VERSION "amr_vehicle K2 v1 (Ausbaupaket K2, Phasenplan v2.1)"

NS_ :

BS_:

BU_: PI_VCU DRIVE_ECU SENSOR_ECU RADAR_ECU

BO_ 272 SENSOR_RANGE: 4 SENSOR_ECU
 SG_ range_front : 0|32@1+ (1,0) [0|4] "m"  PI_VCU

BO_ 288 SENSOR_CLIFF: 1 SENSOR_ECU
 SG_ cliff_detected : 0|8@1+ (1,0) [0|1] ""  PI_VCU,DRIVE_ECU

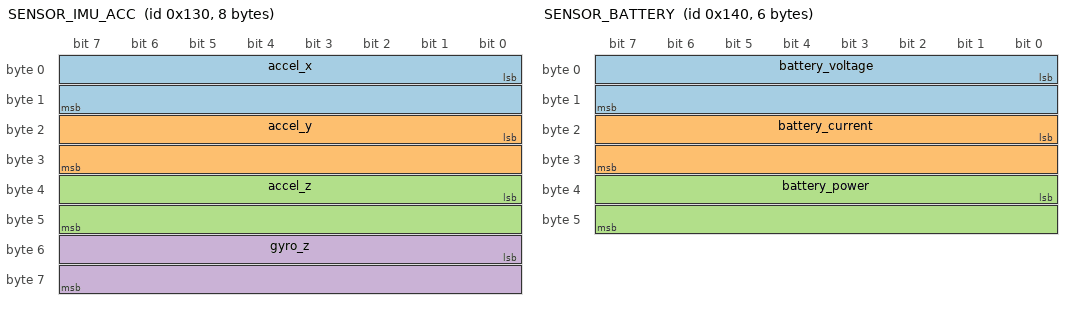
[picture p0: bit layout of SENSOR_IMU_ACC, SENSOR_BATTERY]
BO_ 304 SENSOR_IMU_ACC: 8 SENSOR_ECU
 SG_ accel_x : 0|16@1- (0.001,0) [-32.768|32.767] "m/s^2"  PI_VCU
 SG_ accel_y : 16|16@1- (0.001,0) [-32.768|32.767] "m/s^2"  PI_VCU
 SG_ accel_z : 32|16@1- (0.001,0) [-32.768|32.767] "m/s^2"  PI_VCU
 SG_ gyro_z : 48|16@1- (0.01,0) [-327.68|327.67] "rad/s"  PI_VCU

BO_ 305 SENSOR_IMU_HEADING: 4 SENSOR_ECU
 SG_ heading : 0|32@1+ (1,0) [-3.2|3.2] "rad"  PI_VCU

BO_ 320 SENSOR_BATTERY: 6 SENSOR_ECU
 SG_ battery_voltage : 0|16@1+ (0.001,0) [0|65.535] "V"  PI_VCU
 SG_ battery_current : 16|16@1- (0.001,0) [-32.768|32.767] "A"  PI_VCU
 SG_ battery_power : 32|16@1+ (0.001,0) [0|65.535] "W"  PI_VCU

BO_ 321 SENSOR_BATTERY_SHUTDOWN: 1 SENSOR_ECU
 SG_ battery_shutdown : 0|8@1+ (1,0) [0|1] ""  PI_VCU,DRIVE_ECU

BO_ 336 VCU_SERVO_COMMAND_LEGACY: 4 PI_VCU
 SG_ servo_pan_legacy : 0|16@1- (0.1,0) [-180|180] "deg"  SENSOR_ECU
 SG_ servo_tilt_legacy : 16|16@1- (0.1,0) [-180|180] "deg"  SENSOR_ECU

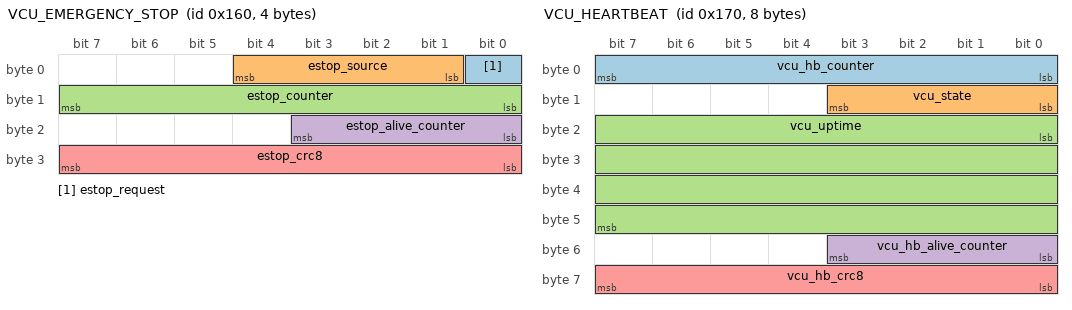
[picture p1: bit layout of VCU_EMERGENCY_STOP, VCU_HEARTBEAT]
BO_ 352 VCU_EMERGENCY_STOP: 4 PI_VCU
 SG_ estop_request : 0|1@1+ (1,0) [0|1] ""  DRIVE_ECU,SENSOR_ECU
 SG_ estop_source : 1|4@1+ (1,0) [0|15] ""  DRIVE_ECU,SENSOR_ECU
 SG_ estop_counter : 8|8@1+ (1,0) [0|255] ""  DRIVE_ECU,SENSOR_ECU
 SG_ estop_alive_counter : 16|4@1+ (1,0) [0|15] ""  DRIVE_ECU,SENSOR_ECU
 SG_ estop_crc8 : 24|8@1+ (1,0) [0|255] ""  DRIVE_ECU,SENSOR_ECU

BO_ 368 VCU_HEARTBEAT: 8 PI_VCU
 SG_ vcu_hb_counter : 0|8@1+ (1,0) [0|255] ""  DRIVE_ECU,SENSOR_ECU
 SG_ vcu_state : 8|4@1+ (1,0) [0|15] ""  DRIVE_ECU,SENSOR_ECU
 SG_ vcu_uptime : 16|32@1+ (1,0) [0|4294967295] "s"  DRIVE_ECU,SENSOR_ECU
 SG_ vcu_hb_alive_counter : 48|4@1+ (1,0) [0|15] ""  DRIVE_ECU,SENSOR_ECU
 SG_ vcu_hb_crc8 : 56|8@1+ (1,0) [0|255] ""  DRIVE_ECU,SENSOR_ECU

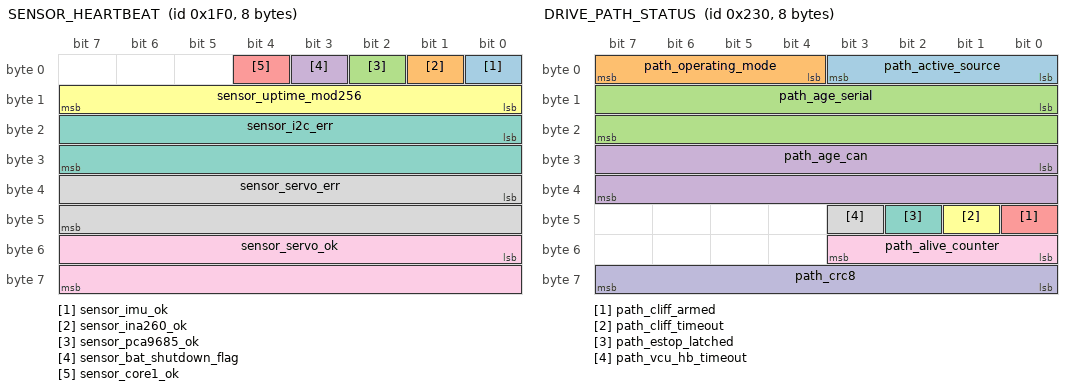
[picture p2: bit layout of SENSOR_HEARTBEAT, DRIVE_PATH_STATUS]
BO_ 496 SENSOR_HEARTBEAT: 8 SENSOR_ECU
 SG_ sensor_imu_ok : 0|1@1+ (1,0) [0|1] ""  PI_VCU
 SG_ sensor_ina260_ok : 1|1@1+ (1,0) [0|1] ""  PI_VCU
 SG_ sensor_pca9685_ok : 2|1@1+ (1,0) [0|1] ""  PI_VCU
 SG_ sensor_bat_shutdown_flag : 3|1@1+ (1,0) [0|1] ""  PI_VCU
 SG_ sensor_core1_ok : 4|1@1+ (1,0) [0|1] ""  PI_VCU
 SG_ sensor_uptime_mod256 : 8|8@1+ (1,0) [0|255] "s"  PI_VCU
 SG_ sensor_i2c_err : 16|16@1+ (1,0) [0|65535] ""  PI_VCU
 SG_ sensor_servo_err : 32|16@1+ (1,0) [0|65535] ""  PI_VCU
 SG_ sensor_servo_ok : 48|16@1+ (1,0) [0|65535] ""  PI_VCU

BO_ 512 DRIVE_ODOM_XY: 8 DRIVE_ECU
 SG_ odom_x : 0|32@1+ (1,0) [-100|100] "m"  PI_VCU
 SG_ odom_y : 32|32@1+ (1,0) [-100|100] "m"  PI_VCU

BO_ 513 DRIVE_ODOM_HEADING_SPEED: 8 DRIVE_ECU
 SG_ odom_theta : 0|32@1+ (1,0) [-3.2|3.2] "rad"  PI_VCU
 SG_ odom_v_linear : 32|32@1+ (1,0) [-1|1] "m/s"  PI_VCU

BO_ 528 DRIVE_WHEEL_SPEED: 8 DRIVE_ECU
 SG_ wheel_speed_left : 0|32@1+ (1,0) [-50|50] "rad/s"  PI_VCU
 SG_ wheel_speed_right : 32|32@1+ (1,0) [-50|50] "rad/s"  PI_VCU

BO_ 544 DRIVE_MOTOR_PWM: 4 DRIVE_ECU
 SG_ motor_pwm_left : 0|16@1- (1,0) [-255|255] ""  PI_VCU
 SG_ motor_pwm_right : 16|16@1- (1,0) [-255|255] ""  PI_VCU

BO_ 560 DRIVE_PATH_STATUS: 8 DRIVE_ECU
 SG_ path_active_source : 0|4@1+ (1,0) [0|15] ""  PI_VCU
 SG_ path_operating_mode : 4|4@1+ (1,0) [0|15] ""  PI_VCU
 SG_ path_age_serial : 8|16@1+ (1,0) [0|65535] "ms"  PI_VCU
 SG_ path_age_can : 24|16@1+ (1,0) [0|65535] "ms"  PI_VCU
 SG_ path_cliff_armed : 40|1@1+ (1,0) [0|1] ""  PI_VCU
 SG_ path_cliff_timeout : 41|1@1+ (1,0) [0|1] ""  PI_VCU
 SG_ path_estop_latched : 42|1@1+ (1,0) [0|1] ""  PI_VCU
 SG_ path_vcu_hb_timeout : 43|1@1+ (1,0) [0|1] ""  PI_VCU
 SG_ path_alive_counter : 48|4@1+ (1,0) [0|15] ""  PI_VCU
 SG_ path_crc8 : 56|8@1+ (1,0) [0|255] ""  PI_VCU

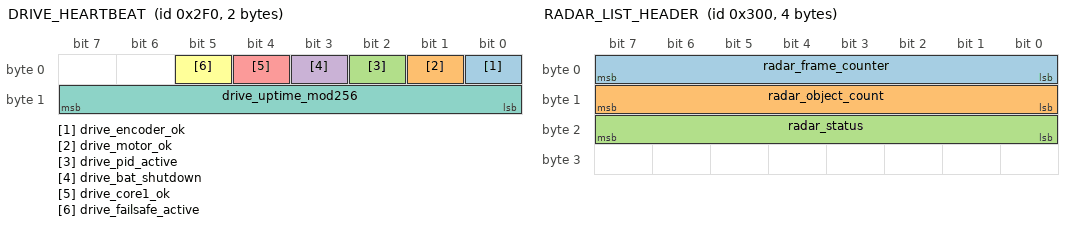
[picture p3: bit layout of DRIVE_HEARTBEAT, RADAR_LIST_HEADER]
BO_ 752 DRIVE_HEARTBEAT: 2 DRIVE_ECU
 SG_ drive_encoder_ok : 0|1@1+ (1,0) [0|1] ""  PI_VCU
 SG_ drive_motor_ok : 1|1@1+ (1,0) [0|1] ""  PI_VCU
 SG_ drive_pid_active : 2|1@1+ (1,0) [0|1] ""  PI_VCU
 SG_ drive_bat_shutdown : 3|1@1+ (1,0) [0|1] ""  PI_VCU
 SG_ drive_core1_ok : 4|1@1+ (1,0) [0|1] ""  PI_VCU
 SG_ drive_failsafe_active : 5|1@1+ (1,0) [0|1] ""  PI_VCU
 SG_ drive_uptime_mod256 : 8|8@1+ (1,0) [0|255] "s"  PI_VCU

BO_ 768 RADAR_LIST_HEADER: 4 RADAR_ECU
 SG_ radar_frame_counter : 0|8@1+ (1,0) [0|255] ""  PI_VCU
 SG_ radar_object_count : 8|8@1+ (1,0) [0|8] ""  PI_VCU
 SG_ radar_status : 16|8@1+ (1,0) [0|255] ""  PI_VCU

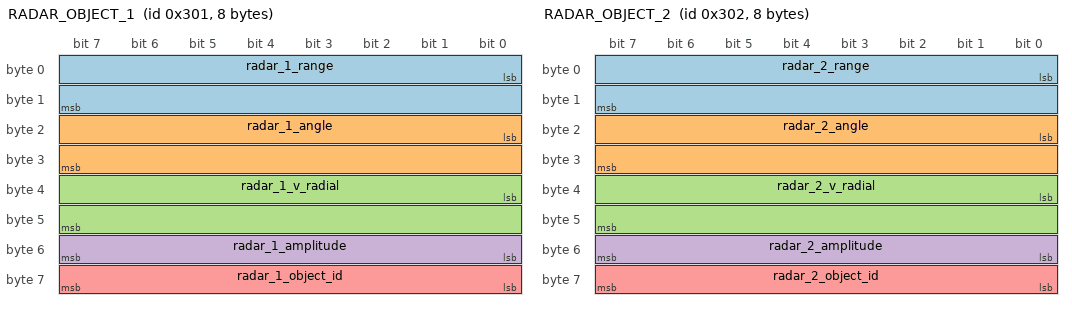
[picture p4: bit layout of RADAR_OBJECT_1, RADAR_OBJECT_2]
BO_ 769 RADAR_OBJECT_1: 8 RADAR_ECU
 SG_ radar_1_range : 0|16@1+ (0.001,0) [0|65.535] "m"  PI_VCU
 SG_ radar_1_angle : 16|16@1- (0.01,0) [-327.68|327.67] "deg"  PI_VCU
 SG_ radar_1_v_radial : 32|16@1- (0.01,0) [-327.68|327.67] "m/s"  PI_VCU
 SG_ radar_1_amplitude : 48|8@1+ (1,0) [0|255] ""  PI_VCU
 SG_ radar_1_object_id : 56|8@1+ (1,0) [0|255] ""  PI_VCU

BO_ 770 RADAR_OBJECT_2: 8 RADAR_ECU
 SG_ radar_2_range : 0|16@1+ (0.001,0) [0|65.535] "m"  PI_VCU
 SG_ radar_2_angle : 16|16@1- (0.01,0) [-327.68|327.67] "deg"  PI_VCU
 SG_ radar_2_v_radial : 32|16@1- (0.01,0) [-327.68|327.67] "m/s"  PI_VCU
 SG_ radar_2_amplitude : 48|8@1+ (1,0) [0|255] ""  PI_VCU
 SG_ radar_2_object_id : 56|8@1+ (1,0) [0|255] ""  PI_VCU

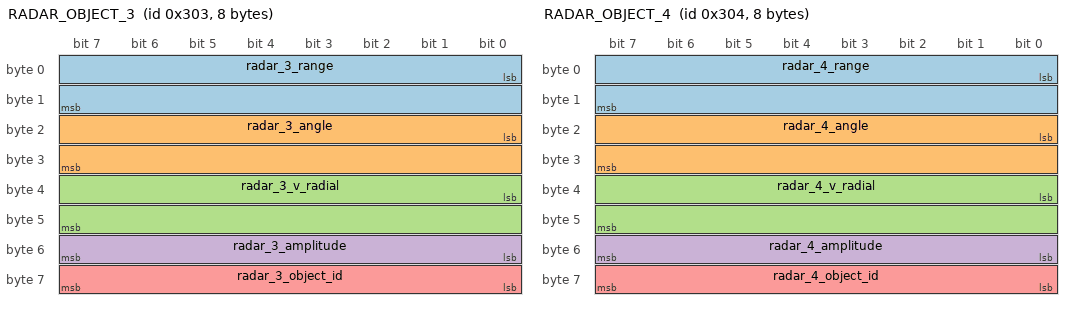
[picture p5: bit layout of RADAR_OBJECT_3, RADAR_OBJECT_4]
BO_ 771 RADAR_OBJECT_3: 8 RADAR_ECU
 SG_ radar_3_range : 0|16@1+ (0.001,0) [0|65.535] "m"  PI_VCU
 SG_ radar_3_angle : 16|16@1- (0.01,0) [-327.68|327.67] "deg"  PI_VCU
 SG_ radar_3_v_radial : 32|16@1- (0.01,0) [-327.68|327.67] "m/s"  PI_VCU
 SG_ radar_3_amplitude : 48|8@1+ (1,0) [0|255] ""  PI_VCU
 SG_ radar_3_object_id : 56|8@1+ (1,0) [0|255] ""  PI_VCU

BO_ 772 RADAR_OBJECT_4: 8 RADAR_ECU
 SG_ radar_4_range : 0|16@1+ (0.001,0) [0|65.535] "m"  PI_VCU
 SG_ radar_4_angle : 16|16@1- (0.01,0) [-327.68|327.67] "deg"  PI_VCU
 SG_ radar_4_v_radial : 32|16@1- (0.01,0) [-327.68|327.67] "m/s"  PI_VCU
 SG_ radar_4_amplitude : 48|8@1+ (1,0) [0|255] ""  PI_VCU
 SG_ radar_4_object_id : 56|8@1+ (1,0) [0|255] ""  PI_VCU

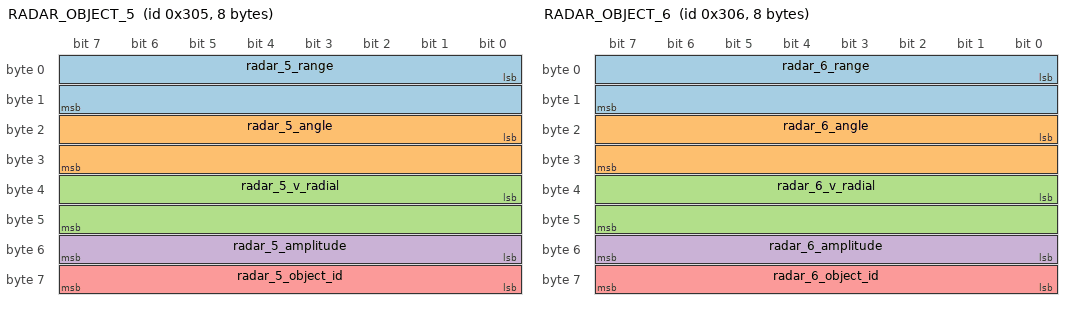
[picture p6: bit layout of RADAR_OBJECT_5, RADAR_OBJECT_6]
BO_ 773 RADAR_OBJECT_5: 8 RADAR_ECU
 SG_ radar_5_range : 0|16@1+ (0.001,0) [0|65.535] "m"  PI_VCU
 SG_ radar_5_angle : 16|16@1- (0.01,0) [-327.68|327.67] "deg"  PI_VCU
 SG_ radar_5_v_radial : 32|16@1- (0.01,0) [-327.68|327.67] "m/s"  PI_VCU
 SG_ radar_5_amplitude : 48|8@1+ (1,0) [0|255] ""  PI_VCU
 SG_ radar_5_object_id : 56|8@1+ (1,0) [0|255] ""  PI_VCU

BO_ 774 RADAR_OBJECT_6: 8 RADAR_ECU
 SG_ radar_6_range : 0|16@1+ (0.001,0) [0|65.535] "m"  PI_VCU
 SG_ radar_6_angle : 16|16@1- (0.01,0) [-327.68|327.67] "deg"  PI_VCU
 SG_ radar_6_v_radial : 32|16@1- (0.01,0) [-327.68|327.67] "m/s"  PI_VCU
 SG_ radar_6_amplitude : 48|8@1+ (1,0) [0|255] ""  PI_VCU
 SG_ radar_6_object_id : 56|8@1+ (1,0) [0|255] ""  PI_VCU

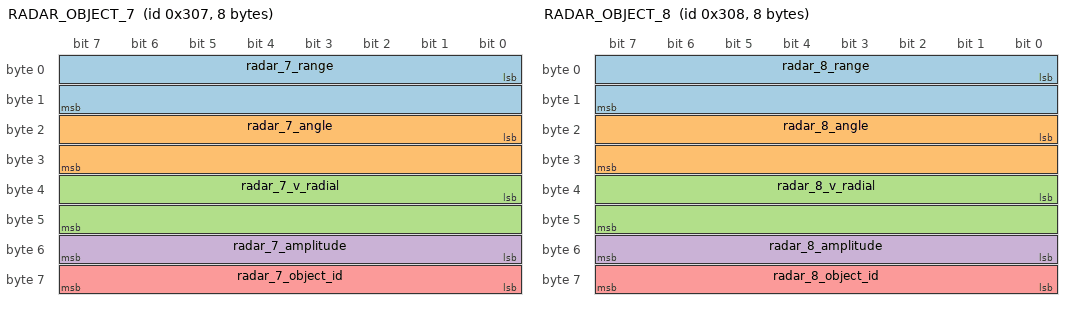
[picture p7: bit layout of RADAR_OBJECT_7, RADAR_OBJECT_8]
BO_ 775 RADAR_OBJECT_7: 8 RADAR_ECU
 SG_ radar_7_range : 0|16@1+ (0.001,0) [0|65.535] "m"  PI_VCU
 SG_ radar_7_angle : 16|16@1- (0.01,0) [-327.68|327.67] "deg"  PI_VCU
 SG_ radar_7_v_radial : 32|16@1- (0.01,0) [-327.68|327.67] "m/s"  PI_VCU
 SG_ radar_7_amplitude : 48|8@1+ (1,0) [0|255] ""  PI_VCU
 SG_ radar_7_object_id : 56|8@1+ (1,0) [0|255] ""  PI_VCU

BO_ 776 RADAR_OBJECT_8: 8 RADAR_ECU
 SG_ radar_8_range : 0|16@1+ (0.001,0) [0|65.535] "m"  PI_VCU
 SG_ radar_8_angle : 16|16@1- (0.01,0) [-327.68|327.67] "deg"  PI_VCU
 SG_ radar_8_v_radial : 32|16@1- (0.01,0) [-327.68|327.67] "m/s"  PI_VCU
 SG_ radar_8_amplitude : 48|8@1+ (1,0) [0|255] ""  PI_VCU
 SG_ radar_8_object_id : 56|8@1+ (1,0) [0|255] ""  PI_VCU

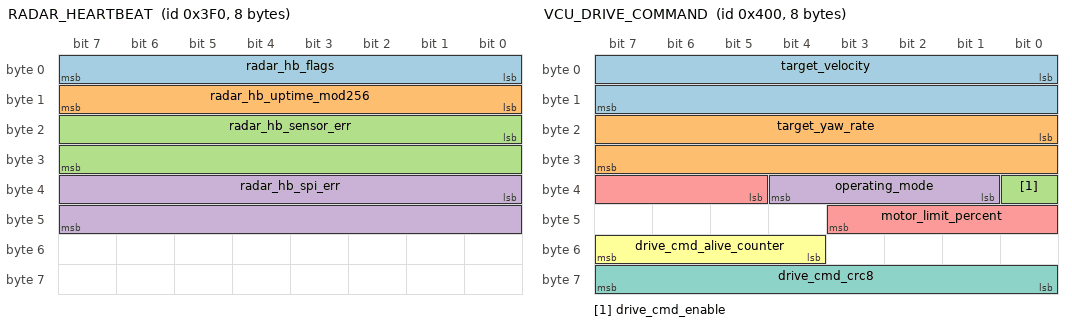
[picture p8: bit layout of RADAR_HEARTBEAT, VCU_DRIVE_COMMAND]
BO_ 1008 RADAR_HEARTBEAT: 8 RADAR_ECU
 SG_ radar_hb_flags : 0|8@1+ (1,0) [0|255] ""  PI_VCU
 SG_ radar_hb_uptime_mod256 : 8|8@1+ (1,0) [0|255] "s"  PI_VCU
 SG_ radar_hb_sensor_err : 16|16@1+ (1,0) [0|65535] ""  PI_VCU
 SG_ radar_hb_spi_err : 32|16@1+ (1,0) [0|65535] ""  PI_VCU

BO_ 1024 VCU_DRIVE_COMMAND: 8 PI_VCU
 SG_ target_velocity : 0|16@1- (0.001,0) [-32.768|32.767] "m/s"  DRIVE_ECU
 SG_ target_yaw_rate : 16|16@1- (0.001,0) [-32.768|32.767] "rad/s"  DRIVE_ECU
 SG_ drive_cmd_enable : 32|1@1+ (1,0) [0|1] ""  DRIVE_ECU
 SG_ operating_mode : 33|4@1+ (1,0) [0|15] ""  DRIVE_ECU
 SG_ motor_limit_percent : 37|7@1+ (1,0) [0|100] "%"  DRIVE_ECU
 SG_ drive_cmd_alive_counter : 52|4@1+ (1,0) [0|15] ""  DRIVE_ECU
 SG_ drive_cmd_crc8 : 56|8@1+ (1,0) [0|255] ""  DRIVE_ECU

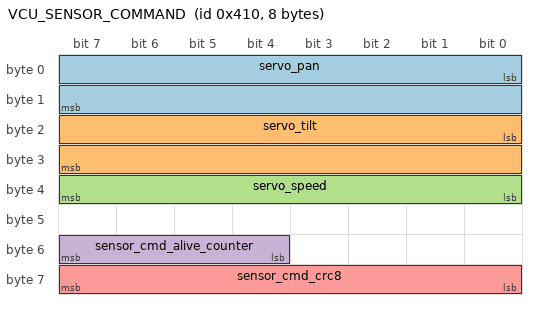
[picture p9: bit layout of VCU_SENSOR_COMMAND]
BO_ 1040 VCU_SENSOR_COMMAND: 8 PI_VCU
 SG_ servo_pan : 0|16@1+ (0.1,0) [0|180] "deg"  SENSOR_ECU
 SG_ servo_tilt : 16|16@1+ (0.1,0) [0|180] "deg"  SENSOR_ECU
 SG_ servo_speed : 32|8@1+ (1,0) [0|255] ""  SENSOR_ECU
 SG_ sensor_cmd_alive_counter : 52|4@1+ (1,0) [0|15] ""  SENSOR_ECU
 SG_ sensor_cmd_crc8 : 56|8@1+ (1,0) [0|255] ""  SENSOR_ECU

CM_ "Signaldatenbank des AMR (Ausbaupaket K2, Phasenplan v2.1).
Alleinige Quelle fuer Kennungen, Nutzdatenlaengen, Bitlagen, Skalierungen und
Zykluszeiten (SA-10). Firmware-Konstanten und die Pi-seitige Dekodierung werden
hieraus abgeleitet, nicht parallel gepflegt.

Byte-Order durchgehend Intel (Little Endian). Die float32-Signale sind ueber
SIG_VALTYPE_ als IEEE-754-Gleitkomma gekennzeichnet und entsprechen dem memcpy
der Firmware.

AUS K1 UEBERNOMMEN
- Betriebsmodi SERIAL_REFERENCE, CAN_SHADOW, CAN_PRIMARY, SERVICE, FAILSAFE
  (anforderungsliste-L1.md, Abschnitt 13.1)
- Zeitueberwachung des CAN-Kommandopfads 300 ms im Modus CAN_PRIMARY
  (anforderungsliste-L1.md, Abschnitt 13.3); SIA-17 mit 500 ms bleibt uebergeordnet
- Pflichtumfang der Signale P-01 bis P-07, D-01 bis D-06, S-01 bis S-07
  (signalbedarf.md); jede Nachricht dieser Datenbank ist einer Zeile zugeordnet
- Ablageort hardware/can-bus/ (signalbedarf.md, Einleitung)
- Sicherheitsrelevante Signale erhalten hoehere Buspriorisierung als
  Diagnosesignale (signalbedarf.md, Abschnitt 7.4)
- Bestehende Kennungen bleiben unveraendert, neue Signale belegen freie Bereiche
  (signalbedarf.md, Abschnitt 7.3)

AUS DER FIRMWARE UEBERNOMMEN (Ist-Zustand, unveraendert)
- Die dreizehn Bestandskennungen 0x110 bis 0x2F0 mit Bitlagen, Skalierungen und
  Nutzdatenlaengen nach twai_can.hpp beider Knoten
  (arbeitsplan-k0-k2-s-a.md, Anhang A.3)

IN K2 VORGESCHLAGEN (nicht aus K1 uebernommen)
- Kennungen 0x160 Notstopp, 0x170 Gateway-Lebenszeichen, 0x230 Pfadstatus,
  0x400 Fahrbefehl, 0x410 Servokommando
- Zahlenwerte des Betriebsmodus-Enums (0 bis 4) und des Notstopp-Quellen-Enums
- Bitlagen, Skalierungen und Nutzdatenlaengen der fuenf neuen Nachrichten
- E2E-Absicherung: alive_counter mit 4 Bit und CRC-8 nach SAE J1850
  (Polynom 0x1D, Startwert 0xFF, Endverknuepfung 0xFF) ueber Byte 0 bis 6
  zuzueglich der Data-ID
- Zykluszeiten 0x200 und 0x201 mit 40 ms sowie 0x210 und 0x220 mit 80 ms
  (Tick-Regel: ganzzahlige Vielfache des Sendertakts von 20 ms; Begruendung
  Messung S-A vorher, arbeitsplan-k0-k2-s-a.md, Abschnitte 3.2 und 3.4)
- Sendeoffsets je Sender (GenMsgStartDelayTime)
- Radar-Reservierung 0x300 bis 0x3F0; Layout in Spike S-B zu bestaetigen

WIRKSAMKEIT
Die fuenf neuen Nachrichten und die geaenderten Zykluszeiten sind in K2
ausschliesslich spezifiziert. Die Firmware sendet weiterhin nach dem Ist-Zustand;
die Umsetzung erfolgt fuer die Sensorbasis in K3 und fuer den Fahrkern in K4.";
CM_ BO_ 272 "S-03 Abstand voraus. Sendebedingung: jede erfolgreiche Ultraschallmessung im 100-ms-Raster.";
CM_ BO_ 288 "S-01 Kantenerkennung. Wird zusaetzlich vom Fahrkern empfangen (Sicherheitspfad ohne Zentralrechner, id_cliff_rx).";
CM_ BO_ 304 "S-04 Beschleunigung und Gierrate. Skalierung nach Firmware: Beschleunigung Faktor 0,001, Gierrate Faktor 0,01.";
CM_ BO_ 305 "S-05 Gierwinkel aus dem Komplementaerfilter der Sensorbasis.";
CM_ BO_ 320 "S-06 Batteriespannung, Strom und Leistung. Die Leistung saettigt bei 65,535 W, der Betriebspunkt liegt bei rund 60 W; die Erweiterung des Wertebereichs erfordert eine Layoutaenderung und ist fuer K3 vorgemerkt.";
CM_ BO_ 321 "S-02 Batterie-Abschaltanforderung. Wird zusaetzlich vom Fahrkern empfangen (id_battery_shutdown_rx). K1 fordert zusaetzlich zur Ereignismeldung eine zyklische Wiederholung mit 1 Hz; die Firmware sendet heute nur ereignisgesteuert, die Umsetzung erfolgt in K3.";
CM_ BO_ 336 "P-07 Servosollwert im Ist-Zustand. Bestehendes Kommando des Zentralrechners an die Sensorbasis, ohne E2E-Absicherung. Bleibt unveraendert bestehen, damit aeltere Firmware betriebsfaehig bleibt; die Ablloesung durch VCU_SENSOR_COMMAND erfolgt in K5.";
CM_ BO_ 352 "P-05 Notstopp-Anforderung an beide Steuergeraete. Kennung unterhalb der Diagnosebereiche, damit die Anforderung die Arbitrierung gegen Diagnoseverkehr gewinnt; Kantenerkennung und Batterieabschaltung bleiben hoeher priorisiert.";
CM_ BO_ 368 "P-06 Lebenszeichen des Gateways. Erlaubt den Steuergeraeten, den Ausfall des Zentralrechners zu erkennen, ohne auf das Ausbleiben von Fahrbefehlen zu warten.";
CM_ BO_ 496 "S-07 Lebenszeichen der Sensorbasis mit Fehlerzaehlern.";
CM_ BO_ 512 "D-01 Odometrie-Position.";
CM_ BO_ 513 "D-02 Odometrie-Gierwinkel und Laengsgeschwindigkeit. Wird im selben Sendertakt wie DRIVE_ODOM_XY uebertragen, damit die Werte zusammengehoeren.";
CM_ BO_ 528 "D-03 Raddrehzahl links und rechts.";
CM_ BO_ 544 "D-04 Stellgroesse links und rechts, ganzzahlig im Bereich -255 bis 255.";
CM_ BO_ 560 "D-05 Status des aktiven Fahrbefehlspfads. Macht die Arbitrierung von aussen beobachtbar und ist Nachweisgrundlage fuer das Failover.";
CM_ BO_ 752 "D-06 Lebenszeichen des Fahrkerns. Die Bits drive_encoder_ok, drive_motor_ok und drive_core1_ok sind in der heutigen Firmware fest auf 1 gesetzt und fuehren noch keinen echten Zustand; die Behebung ist Bestandteil von K3.";
CM_ BO_ 768 "Radar-Platzhalter: Kopf der Objektliste. Layout in Spike S-B zu bestaetigen.";
CM_ BO_ 1008 "Radar-Platzhalter: Lebenszeichen. Layout in Spike S-B zu bestaetigen.";
CM_ BO_ 1024 "P-01, P-02, P-03 und P-04 in einem Rahmen. Bleibt ohne gueltiges Kommando die Zeitueberwachung von 300 ms im Modus CAN_PRIMARY unerfuellt, geht der Fahrkern in FAILSAFE mit v gleich null und omega gleich null; ein selbsttaetiger Quellenwechsel findet nicht statt. Im Modus CAN_SHADOW werden E2E-Fehler nur gezaehlt. Die Begrenzungen nach NFA-05, NFA-06 und NFA-07 wirken im Steuergeraet, nicht im Wertebereich dieses Signals.";
CM_ BO_ 1040 "P-07 Servosollwert mit E2E-Absicherung. Nachfolger von VCU_SERVO_COMMAND_LEGACY; die Umstellung erfolgt in K5, bis dahin ist diese Nachricht spezifiziert und ohne Wirkung.";
CM_ SG_ 320 battery_power "Saettigt bei 65,535 W (S-06).";
CM_ SG_ 1024 motor_limit_percent "P-04 Begrenzung der Stellgroesse in Prozent; ersetzt den heutigen Weg ueber hardware_cmd.";
CM_ SG_ 1024 drive_cmd_crc8 "CRC-8 nach SAE J1850 ueber Byte 0 bis 6 zuzueglich der Data-ID 0x00 (unteres Byte der Kennung 0x400).";
CM_ SG_ 1040 sensor_cmd_crc8 "CRC-8 nach SAE J1850 ueber Byte 0 bis 6 zuzueglich der Data-ID 0x10 (unteres Byte der Kennung 0x410).";
CM_ SG_ 352 estop_crc8 "CRC-8 nach SAE J1850 ueber Byte 0 bis 2 zuzueglich der Data-ID 0x60.";
CM_ SG_ 368 vcu_hb_crc8 "CRC-8 nach SAE J1850 ueber Byte 0 bis 6 zuzueglich der Data-ID 0x70.";
CM_ SG_ 560 path_crc8 "CRC-8 nach SAE J1850 ueber Byte 0 bis 6 zuzueglich der Data-ID 0x30.";
CM_ SG_ 352 estop_counter "Fortlaufender Zaehler nach P-05; macht ein verlorenes Ereignis erkennbar.";
BA_DEF_ BO_  "GenMsgCycleTime" INT 0 65535;
BA_DEF_ BO_  "GenMsgStartDelayTime" INT 0 65535;
BA_DEF_ BO_  "GenMsgSendType" ENUM  "cyclic","event","cyclicAndEvent","noMsgSendType";
BA_DEF_DEF_  "GenMsgCycleTime" 0;
BA_DEF_DEF_  "GenMsgStartDelayTime" 0;
BA_DEF_DEF_  "GenMsgSendType" "noMsgSendType";
BA_ "GenMsgCycleTime" BO_ 272 100;
BA_ "GenMsgStartDelayTime" BO_ 272 15;
BA_ "GenMsgSendType" BO_ 272 0;
BA_ "GenMsgCycleTime" BO_ 288 50;
BA_ "GenMsgStartDelayTime" BO_ 288 5;
BA_ "GenMsgSendType" BO_ 288 0;
BA_ "GenMsgCycleTime" BO_ 304 20;
BA_ "GenMsgSendType" BO_ 304 0;
BA_ "GenMsgCycleTime" BO_ 305 20;
BA_ "GenMsgStartDelayTime" BO_ 305 10;
BA_ "GenMsgSendType" BO_ 305 0;
BA_ "GenMsgCycleTime" BO_ 320 500;
BA_ "GenMsgStartDelayTime" BO_ 320 25;
BA_ "GenMsgSendType" BO_ 320 0;
BA_ "GenMsgCycleTime" BO_ 321 1000;
BA_ "GenMsgStartDelayTime" BO_ 321 45;
BA_ "GenMsgSendType" BO_ 321 2;
BA_ "GenMsgSendType" BO_ 336 1;
BA_ "GenMsgCycleTime" BO_ 352 100;
BA_ "GenMsgSendType" BO_ 352 2;
BA_ "GenMsgCycleTime" BO_ 368 100;
BA_ "GenMsgStartDelayTime" BO_ 368 5;
BA_ "GenMsgSendType" BO_ 368 0;
BA_ "GenMsgCycleTime" BO_ 496 1000;
BA_ "GenMsgStartDelayTime" BO_ 496 35;
BA_ "GenMsgSendType" BO_ 496 0;
BA_ "GenMsgCycleTime" BO_ 512 40;
BA_ "GenMsgSendType" BO_ 512 0;
BA_ "GenMsgCycleTime" BO_ 513 40;
BA_ "GenMsgSendType" BO_ 513 0;
BA_ "GenMsgCycleTime" BO_ 528 80;
BA_ "GenMsgStartDelayTime" BO_ 528 20;
BA_ "GenMsgSendType" BO_ 528 0;
BA_ "GenMsgCycleTime" BO_ 544 80;
BA_ "GenMsgStartDelayTime" BO_ 544 60;
BA_ "GenMsgSendType" BO_ 544 0;
BA_ "GenMsgCycleTime" BO_ 560 200;
BA_ "GenMsgStartDelayTime" BO_ 560 40;
BA_ "GenMsgSendType" BO_ 560 0;
BA_ "GenMsgCycleTime" BO_ 752 1000;
BA_ "GenMsgStartDelayTime" BO_ 752 60;
BA_ "GenMsgSendType" BO_ 752 0;
BA_ "GenMsgCycleTime" BO_ 768 100;
BA_ "GenMsgSendType" BO_ 768 0;
BA_ "GenMsgCycleTime" BO_ 769 100;
BA_ "GenMsgSendType" BO_ 769 0;
BA_ "GenMsgCycleTime" BO_ 770 100;
BA_ "GenMsgSendType" BO_ 770 0;
BA_ "GenMsgCycleTime" BO_ 771 100;
BA_ "GenMsgSendType" BO_ 771 0;
BA_ "GenMsgCycleTime" BO_ 772 100;
BA_ "GenMsgSendType" BO_ 772 0;
BA_ "GenMsgCycleTime" BO_ 773 100;
BA_ "GenMsgSendType" BO_ 773 0;
BA_ "GenMsgCycleTime" BO_ 774 100;
BA_ "GenMsgSendType" BO_ 774 0;
BA_ "GenMsgCycleTime" BO_ 775 100;
BA_ "GenMsgSendType" BO_ 775 0;
BA_ "GenMsgCycleTime" BO_ 776 100;
BA_ "GenMsgSendType" BO_ 776 0;
BA_ "GenMsgCycleTime" BO_ 1008 1000;
BA_ "GenMsgStartDelayTime" BO_ 1008 50;
BA_ "GenMsgSendType" BO_ 1008 0;
BA_ "GenMsgCycleTime" BO_ 1024 20;
BA_ "GenMsgSendType" BO_ 1024 0;
BA_ "GenMsgCycleTime" BO_ 1040 100;
BA_ "GenMsgStartDelayTime" BO_ 1040 5;
BA_ "GenMsgSendType" BO_ 1040 0;
VAL_ 288 cliff_detected 0 "NO_CLIFF" 1 "CLIFF" ;
VAL_ 321 battery_shutdown 0 "OK" 1 "SHUTDOWN" ;
VAL_ 352 estop_source 0 "NONE" 1 "DASHBOARD" 2 "VOICE" 3 "SAFETY_NODE" 4 "NAVIGATION" 5 "WATCHDOG" ;
VAL_ 368 vcu_state 0 "SERIAL_REFERENCE" 1 "CAN_SHADOW" 2 "CAN_PRIMARY" 3 "SERVICE" 4 "FAILSAFE" ;
VAL_ 560 path_active_source 0 "NONE" 1 "SERIAL_REFERENCE" 2 "CAN" ;
VAL_ 560 path_operating_mode 0 "SERIAL_REFERENCE" 1 "CAN_SHADOW" 2 "CAN_PRIMARY" 3 "SERVICE" 4 "FAILSAFE" ;
VAL_ 1024 operating_mode 0 "SERIAL_REFERENCE" 1 "CAN_SHADOW" 2 "CAN_PRIMARY" 3 "SERVICE" 4 "FAILSAFE" ;
SIG_VALTYPE_ 272 range_front : 1;
SIG_VALTYPE_ 305 heading : 1;
SIG_VALTYPE_ 512 odom_x : 1;
SIG_VALTYPE_ 512 odom_y : 1;
SIG_VALTYPE_ 513 odom_theta : 1;
SIG_VALTYPE_ 513 odom_v_linear : 1;
SIG_VALTYPE_ 528 wheel_speed_left : 1;
SIG_VALTYPE_ 528 wheel_speed_right : 1;
